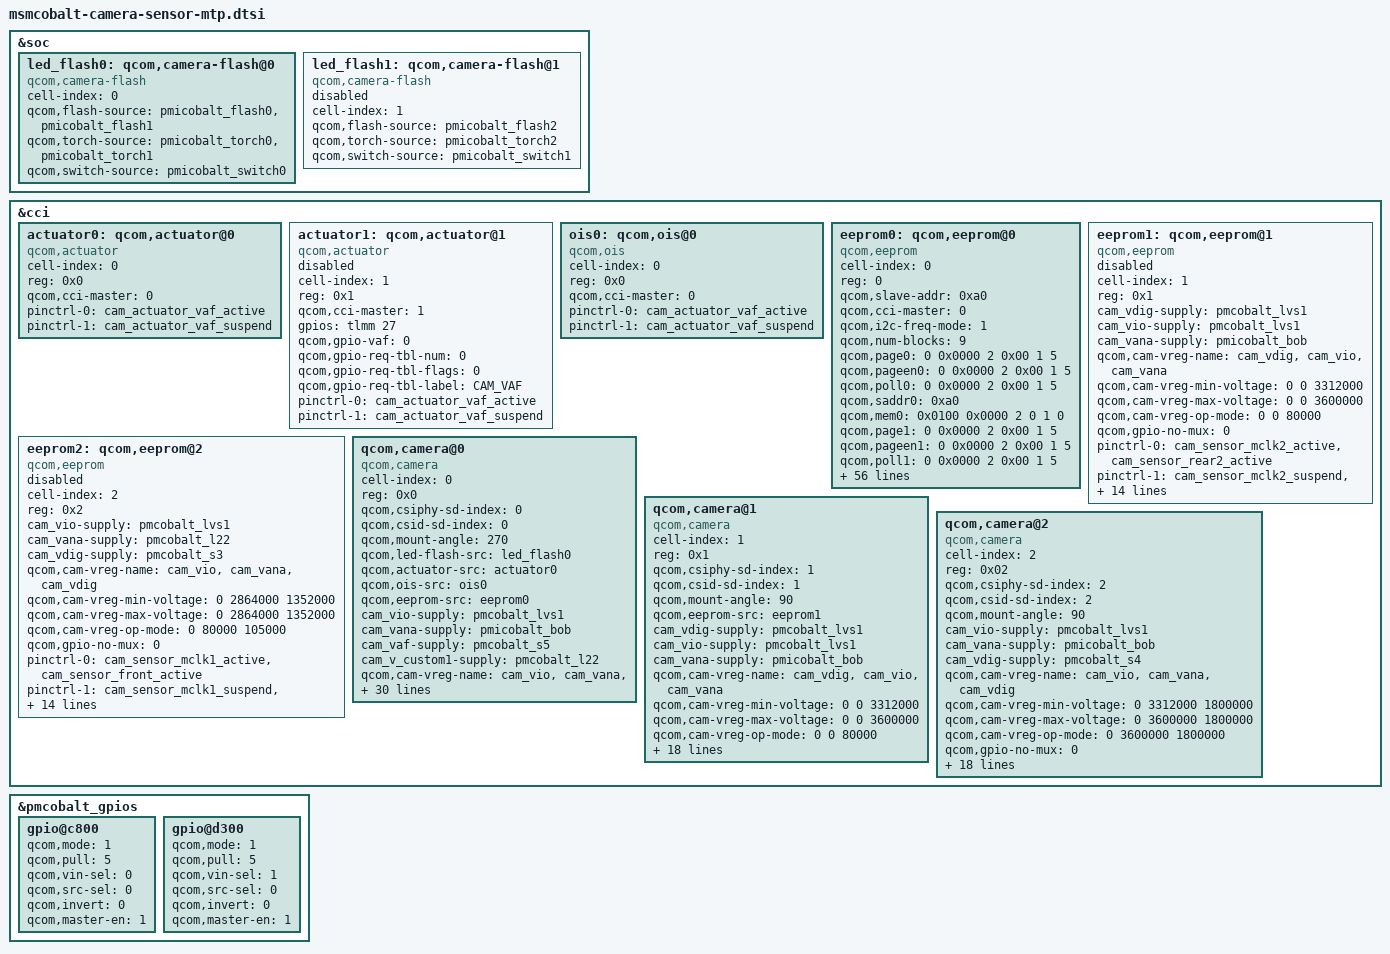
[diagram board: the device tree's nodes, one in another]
/*
 * Copyright (c) 2016, The Linux Foundation. All rights reserved.
 *
 * This program is free software; you can redistribute it and/or modify
 * it under the terms of the GNU General Public License version 2 and
 * only version 2 as published by the Free Software Foundation.
 *
 * This program is distributed in the hope that it will be useful,
 * but WITHOUT ANY WARRANTY; without even the implied warranty of
 * MERCHANTABILITY or FITNESS FOR A PARTICULAR PURPOSE.  See the
 * GNU General Public License for more details.
 */

&soc {
	led_flash0: qcom,camera-flash@0 {
		cell-index = <0>;
		compatible = "qcom,camera-flash";
		qcom,flash-source = <&pmicobalt_flash0 &pmicobalt_flash1>;
		qcom,torch-source = <&pmicobalt_torch0 &pmicobalt_torch1>;
		qcom,switch-source = <&pmicobalt_switch0>;
		status = "ok";
	};

	led_flash1: qcom,camera-flash@1 {
		cell-index = <1>;
		compatible = "qcom,camera-flash";
		qcom,flash-source = <&pmicobalt_flash2>;
		qcom,torch-source = <&pmicobalt_torch2>;
		qcom,switch-source = <&pmicobalt_switch1>;
		status = "disabled";
	};
};

&cci {
	actuator0: qcom,actuator@0 {
		cell-index = <0>;
		reg = <0x0>;
		compatible = "qcom,actuator";
		qcom,cci-master = <0>;
/*
		gpios = <&tlmm 6 0>;
		qcom,gpio-vaf = <0>;
		qcom,gpio-req-tbl-num = <0>;
		qcom,gpio-req-tbl-flags = <0>;
		qcom,gpio-req-tbl-label = "CAM_VAF";
*/
		pinctrl-names = "cam_default", "cam_suspend";
		pinctrl-0 = <&cam_actuator_vaf_active>;
		pinctrl-1 = <&cam_actuator_vaf_suspend>;
		status = "ok";
	};

	actuator1: qcom,actuator@1 {
		cell-index = <1>;
		reg = <0x1>;
		compatible = "qcom,actuator";
		qcom,cci-master = <1>;
		gpios = <&tlmm 27 0>;
		qcom,gpio-vaf = <0>;
		qcom,gpio-req-tbl-num = <0>;
		qcom,gpio-req-tbl-flags = <0>;
		qcom,gpio-req-tbl-label = "CAM_VAF";
		pinctrl-names = "cam_default", "cam_suspend";
		pinctrl-0 = <&cam_actuator_vaf_active>;
		pinctrl-1 = <&cam_actuator_vaf_suspend>;
		status = "disabled";
	};

	ois0: qcom,ois@0 {
		cell-index = <0>;
		reg = <0x0>;
		compatible = "qcom,ois";
		qcom,cci-master = <0>;
/*
		gpios = <&tlmm 6 0>;
		qcom,gpio-vaf = <0>;
		qcom,gpio-req-tbl-num = <0>;
		qcom,gpio-req-tbl-flags = <0>;
		qcom,gpio-req-tbl-label = "CAM_VAF";
*/
		pinctrl-names = "cam_default", "cam_suspend";
		pinctrl-0 = <&cam_actuator_vaf_active>;
		pinctrl-1 = <&cam_actuator_vaf_suspend>;
		status = "ok";
	};

	eeprom0: qcom,eeprom@0 {
		cell-index = <0>;
		reg = <0>;
		compatible = "qcom,eeprom";
//		qcom,eeprom-name = "sony_imx398";// eeprom will be probed in userspace
		qcom,slave-addr = <0xa0>;
		qcom,cci-master = <0>;
		qcom,i2c-freq-mode = <1>;
		qcom,num-blocks = <9>;

		qcom,page0 = <0 0x0000 2 0x00 1 5>;
		qcom,pageen0 = <0 0x0000 2 0x00 1 5>;
		qcom,poll0 = <0 0x0000 2 0x00 1 5>;
		qcom,saddr0 = <0xa0>;
		qcom,mem0 = <0x0100 0x0000 2 0 1 0>;

		qcom,page1 = <0 0x0000 2 0x00 1 5>;
		qcom,pageen1 = <0 0x0000 2 0x00 1 5>;
		qcom,poll1 = <0 0x0000 2 0x00 1 5>;
		qcom,saddr1 = <0xa0>;
		qcom,mem1 = <0x0100 0x0100 2 0 1 0>;

		qcom,page2 = <0 0x0000 2 0x00 1 5>;
		qcom,pageen2 = <0 0x0000 2 0x00 1 5>;
		qcom,poll2 = <0 0x0000 2 0x00 1 5>;
		qcom,saddr2 = <0xa0>;
		qcom,mem2 = <0x0100 0x0200 2 0 1 0>;

		qcom,page3 = <0 0x0000 2 0x00 1 5>;
		qcom,pageen3 = <0 0x0000 2 0x00 1 5>;
		qcom,poll3 = <0 0x0000 2 0x00 1 5>;
		qcom,saddr3 = <0xa0>;
		qcom,mem3 = <0x0100 0x0300 2 0 1 0>;

		qcom,page4 = <0 0x0000 2 0x00 1 5>;
		qcom,pageen4 = <0 0x0000 2 0x00 1 5>;
		qcom,poll4 = <0 0x0000 2 0x00 1 5>;
		qcom,saddr4 = <0xa0>;
		qcom,mem4 = <0x0100 0x0400 2 0 1 0>;

		qcom,page5 = <0 0x0000 2 0x00 1 5>;
		qcom,pageen5 = <0 0x0000 2 0x00 1 5>;
		qcom,poll5 = <0 0x0000 2 0x00 1 5>;
		qcom,saddr5 = <0xa0>;
		qcom,mem5 = <0x0100 0x0500 2 0 1 0>;

		qcom,page6 = <0 0x0000 2 0x00 1 5>;
		qcom,pageen6 = <0 0x0000 2 0x00 1 5>;
		qcom,poll6 = <0 0x0000 2 0x00 1 5>;
		qcom,saddr6 = <0xa0>;
		qcom,mem6 = <0x0100 0x0600 2 0 1 0>;

		qcom,page7 = <0 0x0000 2 0x00 1 5>;
		qcom,pageen7 = <0 0x0000 2 0x00 1 5>;
		qcom,poll7 = <0 0x0000 2 0x00 1 5>;
		qcom,saddr7 = <0xa0>;
		qcom,mem7 = <0x0100 0x0700 2 0 1 0>;

		qcom,page8 = <0 0x0000 2 0x00 1 5>;
		qcom,pageen8 = <0 0x0000 2 0x00 1 5>;
		qcom,poll8 = <0 0x0000 2 0x00 1 5>;
		qcom,saddr8 = <0xa0>;
		qcom,mem8 = <0x0100 0x0800 2 0 1 0>;

		cam_vio-supply = <&pmcobalt_lvs1>;
		qcom,cam-vreg-name = "cam_vio";
		qcom,cam-vreg-min-voltage = <0>;
		qcom,cam-vreg-max-voltage = <0>;
		qcom,cam-vreg-op-mode = <0>;

		pinctrl-names = "cam_default", "cam_suspend";
		pinctrl-0 = <&cam_sensor_rear_active>;
		pinctrl-1 = <&cam_sensor_rear_suspend>;
		gpios = <&tlmm 29 0>;
		qcom,gpio-vio = <0>;
		qcom,gpio-req-tbl-num = <0>;
		qcom,gpio-req-tbl-flags = <0>;
		qcom,gpio-req-tbl-label = "CAM_VIO";

		qcom,cam-power-seq-type = "sensor_vreg";
		qcom,cam-power-seq-val = "cam_vio";
		qcom,cam-power-seq-cfg-val = <1>;
		qcom,cam-power-seq-delay = <1>;

		clocks = <&clock_mmss clk_mclk2_clk_src>,
			<&clock_mmss clk_mmss_camss_mclk2_clk>;
		clock-names = "cam_src_clk", "cam_clk";
		qcom,clock-rates = <24000000 0>;
		status = "ok";
	};

	eeprom1: qcom,eeprom@1 {
		cell-index = <1>;
		reg = <0x1>;
		compatible = "qcom,eeprom";
		cam_vdig-supply = <&pmcobalt_lvs1>;
		cam_vio-supply = <&pmcobalt_lvs1>;
		cam_vana-supply = <&pmicobalt_bob>;
		qcom,cam-vreg-name = "cam_vdig", "cam_vio", "cam_vana";
		qcom,cam-vreg-min-voltage = <0 0 3312000>;
		qcom,cam-vreg-max-voltage = <0 0 3600000>;
		qcom,cam-vreg-op-mode = <0 0 80000>;
		qcom,gpio-no-mux = <0>;
		pinctrl-names = "cam_default", "cam_suspend";
		pinctrl-0 = <&cam_sensor_mclk2_active
				 &cam_sensor_rear2_active>;
		pinctrl-1 = <&cam_sensor_mclk2_suspend
				 &cam_sensor_rear2_suspend>;
		gpios = <&tlmm 15 0>,
			<&tlmm 9 0>,
			<&tlmm 8 0>;
		qcom,gpio-reset = <1>;
		qcom,gpio-vana = <2>;
		qcom,gpio-req-tbl-num = <0 1 2>;
		qcom,gpio-req-tbl-flags = <1 0 0>;
		qcom,gpio-req-tbl-label = "CAMIF_MCLK1",
					  "CAM_RESET1",
					  "CAM_VANA1";
		qcom,sensor-position = <0>;
		qcom,sensor-mode = <0>;
		qcom,cci-master = <1>;
		clocks = <&clock_mmss clk_mclk2_clk_src>,
			<&clock_mmss clk_mmss_camss_mclk2_clk>;
		clock-names = "cam_src_clk", "cam_clk";
		qcom,clock-rates = <24000000 0>;
		status = "disabled";
	};

	eeprom2: qcom,eeprom@2 {
		cell-index = <2>;
		reg = <0x2>;
		compatible = "qcom,eeprom";
		cam_vio-supply = <&pmcobalt_lvs1>;
		cam_vana-supply = <&pmcobalt_l22>;
		cam_vdig-supply = <&pmcobalt_s3>;
		qcom,cam-vreg-name = "cam_vio", "cam_vana", "cam_vdig";
		qcom,cam-vreg-min-voltage =
			<0 2864000 1352000>;
		qcom,cam-vreg-max-voltage =
			<0 2864000 1352000>;
		qcom,cam-vreg-op-mode = <0 80000 105000>;
		qcom,gpio-no-mux = <0>;
		pinctrl-names = "cam_default", "cam_suspend";
		pinctrl-0 = <&cam_sensor_mclk1_active
				 &cam_sensor_front_active>;
		pinctrl-1 = <&cam_sensor_mclk1_suspend
				 &cam_sensor_front_suspend>;
		gpios = <&tlmm 14 0>,
			<&tlmm 28 0>,
			<&pmcobalt_gpios 9 0>;
		qcom,gpio-reset = <1>;
		qcom,gpio-vdig = <2>;
		qcom,gpio-req-tbl-num = <0 1 2>;
		qcom,gpio-req-tbl-flags = <1 0 0>;
		qcom,gpio-req-tbl-label = "CAMIF_MCLK2",
					"CAM_RESET2",
					"CAM_VDIG";
		qcom,sensor-position = <1>;
		qcom,sensor-mode = <0>;
		qcom,cci-master = <1>;
		clocks = <&clock_mmss clk_mclk1_clk_src>,
			<&clock_mmss clk_mmss_camss_mclk1_clk>;
		clock-names = "cam_src_clk", "cam_clk";
		qcom,clock-rates = <24000000 0>;
		status = "disabled";
	};

	qcom,camera@0 {
		cell-index = <0>;
		compatible = "qcom,camera";
		reg = <0x0>;
		qcom,csiphy-sd-index = <0>;
		qcom,csid-sd-index = <0>;
		qcom,mount-angle = <270>;
		qcom,led-flash-src = <&led_flash0>;
		qcom,actuator-src = <&actuator0>;
		qcom,ois-src = <&ois0>;
		qcom,eeprom-src = <&eeprom0>;
		cam_vio-supply = <&pmcobalt_lvs1>;
		cam_vana-supply = <&pmicobalt_bob>;
		cam_vaf-supply = <&pmcobalt_s5>;
		cam_v_custom1-supply = <&pmcobalt_l22>;
		qcom,cam-vreg-name = "cam_vio", "cam_vana", "cam_vaf", "cam_v_custom1";
		qcom,cam-vreg-min-voltage = <0 3312000 1904000 2864000>;
		qcom,cam-vreg-max-voltage = <0 3600000 2040000 2864000>;
		qcom,cam-vreg-op-mode = <0 3600000 2040000 2864000>;
		qcom,gpio-no-mux = <0>;
		pinctrl-names = "cam_default", "cam_suspend";
		pinctrl-0 = <&cam_sensor_mclk0_active
				 &cam_sensor_rear_active
				 &cam_ana_active
				 &cam_actuator_vaf_active>;
		pinctrl-1 = <&cam_sensor_mclk0_suspend
				 &cam_sensor_rear_suspend
				 &cam_ana_suspend
				 &cam_actuator_vaf_suspend>;
		gpios = <&tlmm 13 0>, // mclk
			<&tlmm 30 0>, // reset
			<&tlmm 29 0>, // digital enable
			<&tlmm 27 0>, // ana enable
			<&tlmm 6 0>; // AF enable
		qcom,gpio-reset = <1>;
		qcom,gpio-vdig = <2>;
		qcom,gpio-vana = <3>;
		qcom,gpio-vaf = <4>;
		qcom,gpio-req-tbl-num = <0 1 2 3 4>;
		qcom,gpio-req-tbl-flags = <1 0 0 0 0>;
		qcom,gpio-req-tbl-label = "CAMIF_MCLK0",
					"CAM_RESET0",
					"CAM_VDIG0",
					"CAM_VANA0",
					"CAM_AF_EN0";
		qcom,sensor-position = <0>;
		qcom,sensor-mode = <0>;
		qcom,cci-master = <0>;
		status = "ok";
		clocks = <&clock_mmss clk_mclk0_clk_src>,
				<&clock_mmss clk_mmss_camss_mclk0_clk>;
		clock-names = "cam_src_clk", "cam_clk";
		qcom,clock-rates = <24000000 0>;
	};

	qcom,camera@1 {
		cell-index = <1>;
		compatible = "qcom,camera";
		reg = <0x1>;
		qcom,csiphy-sd-index = <1>;
		qcom,csid-sd-index = <1>;
		qcom,mount-angle = <90>;
		qcom,eeprom-src = <&eeprom1>;
		cam_vdig-supply = <&pmcobalt_lvs1>;
		cam_vio-supply = <&pmcobalt_lvs1>;
		cam_vana-supply = <&pmicobalt_bob>;
		qcom,cam-vreg-name = "cam_vdig", "cam_vio", "cam_vana";
		qcom,cam-vreg-min-voltage = <0 0 3312000>;
		qcom,cam-vreg-max-voltage = <0 0 3600000>;
		qcom,cam-vreg-op-mode = <0 0 80000>;
		qcom,gpio-no-mux = <0>;
		pinctrl-names = "cam_default", "cam_suspend";
		pinctrl-0 = <&cam_sensor_mclk2_active
				 &cam_sensor_rear2_active>;
		pinctrl-1 = <&cam_sensor_mclk2_suspend
				 &cam_sensor_rear2_suspend>;
		gpios = <&tlmm 15 0>,
			<&tlmm 9 0>,
			<&tlmm 8 0>;
		qcom,gpio-reset = <1>;
		qcom,gpio-vana = <2>;
		qcom,gpio-req-tbl-num = <0 1 2>;
		qcom,gpio-req-tbl-flags = <1 0 0>;
		qcom,gpio-req-tbl-label = "CAMIF_MCLK1",
					  "CAM_RESET1",
					  "CAM_VANA1";
		qcom,sensor-position = <0>;
		qcom,sensor-mode = <0>;
		qcom,cci-master = <1>;
		status = "ok";
		clocks = <&clock_mmss clk_mclk2_clk_src>,
			<&clock_mmss clk_mmss_camss_mclk2_clk>;
		clock-names = "cam_src_clk", "cam_clk";
		qcom,clock-rates = <24000000 0>;
	};

	qcom,camera@2 {
		cell-index = <2>;
		compatible = "qcom,camera";
		reg = <0x02>;
		qcom,csiphy-sd-index = <2>;
		qcom,csid-sd-index = <2>;
		qcom,mount-angle = <90>;
		//qcom,eeprom-src = <&eeprom2>;
		//qcom,led-flash-src = <&led_flash1>;
		//qcom,actuator-src = <&actuator1>;
		cam_vio-supply = <&pmcobalt_lvs1>;
		cam_vana-supply = <&pmicobalt_bob>;
		cam_vdig-supply = <&pmcobalt_s4>;
		qcom,cam-vreg-name = "cam_vio", "cam_vana", "cam_vdig";
		qcom,cam-vreg-min-voltage = <0 3312000 1800000>;
		qcom,cam-vreg-max-voltage = <0 3600000 1800000>;
		qcom,cam-vreg-op-mode = <0 3600000 1800000>;
		qcom,gpio-no-mux = <0>;
		pinctrl-names = "cam_default", "cam_suspend";
		pinctrl-0 = <&cam_sensor_mclk1_active
				 &cam_sensor_front_active>;
		pinctrl-1 = <&cam_sensor_mclk1_suspend
				 &cam_sensor_front_suspend>;
		gpios = <&tlmm 14 0>,// mclk
			<&tlmm 28 0>,// reset
			<&tlmm 8 0>,// vdig enable
			<&tlmm 27 0>;// vana enable
		qcom,gpio-reset = <1>;
		qcom,gpio-vdig = <2>;
		qcom,gpio-vana = <3>;
		qcom,gpio-req-tbl-num = <0 1 2 3>;
		qcom,gpio-req-tbl-flags = <1 0 0 0>;
		qcom,gpio-req-tbl-label = "CAMIF_MCLK2",
					  "CAM_RESET2",
					  "CAM_VDIG2",
					  "CAM_VANA2";
		qcom,sensor-position = <1>;
		qcom,sensor-mode = <0>;
		qcom,cci-master = <1>;
		status = "ok";
		clocks = <&clock_mmss clk_mclk1_clk_src>,
			<&clock_mmss clk_mmss_camss_mclk1_clk>;
		clock-names = "cam_src_clk", "cam_clk";
		qcom,clock-rates = <24000000 0>;
	};
};
&pmcobalt_gpios {
	gpio@c800 { /* GPIO 9 - CAMERA SENSOR 2 VDIG */
		qcom,mode = <1>;		/* Output */
		qcom,pull = <5>;		/* No Pull */
		qcom,vin-sel = <0>;		/* VIN1 GPIO_LV */
		qcom,src-sel = <0>;		/* GPIO */
		qcom,invert = <0>;		/* Invert */
		qcom,master-en = <1>;		/* Enable GPIO */
		status = "ok";
	};

	gpio@d300 { /* GPIO 20 - CAMERA SENSOR 0 VDIG */
		qcom,mode = <1>;		/* Output */
		qcom,pull = <5>;		/* No Pull */
		qcom,vin-sel = <1>;		/* VIN1 GPIO_MV */
		qcom,src-sel = <0>;		/* GPIO */
		qcom,invert = <0>;		/* Invert */
		qcom,master-en = <1>;		/* Enable GPIO */
		status = "ok";
	};
};
